# ATSAMC21N18A register map
Registers are 32-bit, access not given, no defined reset value unless marked. A register's access mark holds for its fields unless they carry their own. Addresses are absolute; registers are grouped by the start of their names; [hi:lo] are bit positions; {n}, {i} and the like mark numbered series.

## TSENS
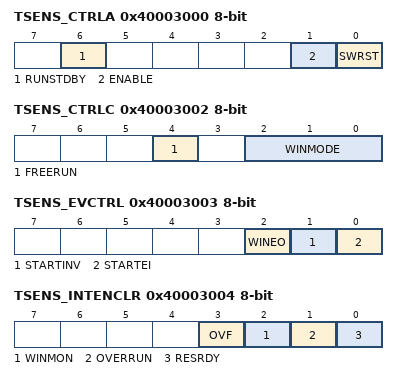
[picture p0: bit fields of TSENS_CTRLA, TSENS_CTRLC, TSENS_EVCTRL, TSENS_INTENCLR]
0x40003000 TSENS_CTRLA 8-bit — Control A Register
  [6] RUNSTDBY, [1] ENABLE, [0] SWRST
0x40003001 TSENS_CTRLB 8-bit — Control B Register
  [0] START
0x40003002 TSENS_CTRLC 8-bit — Control C Register
  [4] FREERUN, [2:0] WINMODE
0x40003003 TSENS_EVCTRL 8-bit — Event Control Register
  [2] WINEO, [1] STARTINV, [0] STARTEI
0x40003004 TSENS_INTENCLR 8-bit — Interrupt Enable Clear Register
  [3] OVF, [2] WINMON, [1] OVERRUN, [0] RESRDY
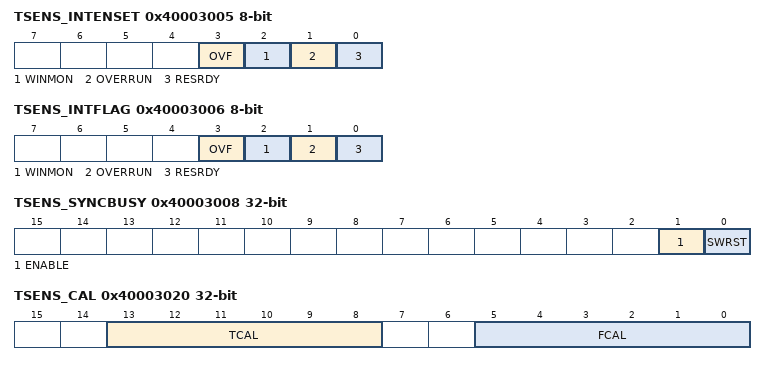
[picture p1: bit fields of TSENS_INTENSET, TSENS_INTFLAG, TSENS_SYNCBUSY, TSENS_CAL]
0x40003005 TSENS_INTENSET 8-bit — Interrupt Enable Set Register
  [3] OVF, [2] WINMON, [1] OVERRUN, [0] RESRDY
0x40003006 TSENS_INTFLAG 8-bit — Interrupt Flag Status and Clear Register
  [3] OVF, [2] WINMON, [1] OVERRUN, [0] RESRDY
0x40003007 TSENS_STATUS 8-bit — Status Register
  [0] OVF
0x40003008 TSENS_SYNCBUSY — Synchronization Busy Register
  [1] ENABLE, [0] SWRST
0x4000300C TSENS_VALUE — Value Register
  [23:0] VALUE
0x40003010 TSENS_WINLT — Window Monitor Lower Threshold Register
  [23:0] WINLT
0x40003014 TSENS_WINUT — Window Monitor Upper Threshold Register
  [23:0] WINUT
0x40003018 TSENS_GAIN — Gain Register
  [23:0] GAIN
0x4000301C TSENS_OFFSET — Offset Register
  [23:0] OFFSETC
0x40003020 TSENS_CAL — Calibration Register
  [13:8] TCAL, [5:0] FCAL
0x40003024 TSENS_DBGCTRL 8-bit — Debug Control Register
  [0] DBGRUN

## WDT
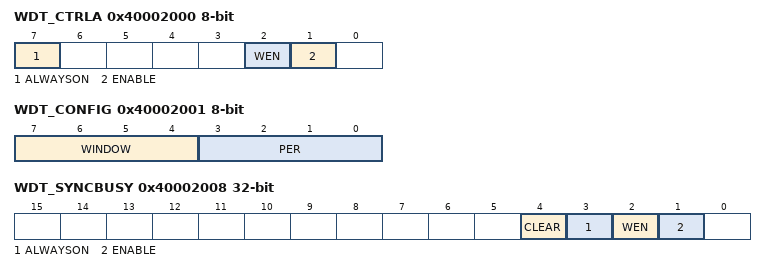
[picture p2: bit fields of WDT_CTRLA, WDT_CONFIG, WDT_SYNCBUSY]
0x40002000 WDT_CTRLA 8-bit — Control
  [7] ALWAYSON, [2] WEN, [1] ENABLE
0x40002001 WDT_CONFIG 8-bit — Configuration
  [7:4] WINDOW, [3:0] PER
0x40002002 WDT_EWCTRL 8-bit — Early Warning Interrupt Control
  [3:0] EWOFFSET
0x40002004 WDT_INTENCLR 8-bit — Interrupt Enable Clear
  [0] EW
0x40002005 WDT_INTENSET 8-bit — Interrupt Enable Set
  [0] EW
0x40002006 WDT_INTFLAG 8-bit — Interrupt Flag Status and Clear
  [0] EW
0x40002008 WDT_SYNCBUSY — Synchronization Busy
  [4] CLEAR, [3] ALWAYSON, [2] WEN, [1] ENABLE
0x4000200C WDT_CLEAR 8-bit — Clear

## MPU
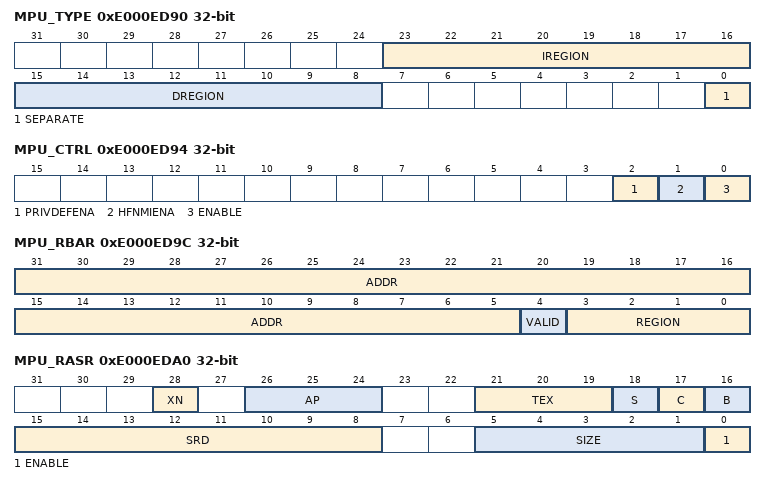
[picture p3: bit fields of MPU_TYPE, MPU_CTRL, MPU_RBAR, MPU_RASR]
0xE000ED90 MPU_TYPE
  [23:16] IREGION, [15:8] DREGION, [0] SEPARATE
0xE000ED94 MPU_CTRL — MPU Control Register
  [2] PRIVDEFENA, [1] HFNMIENA, [0] ENABLE
0xE000ED98 MPU_RNR — MPU Region Number Register
  [7:0] REGION
0xE000ED9C MPU_RBAR — MPU Region Base Address Register
  [31:5] ADDR, [4] VALID, [3:0] REGION
0xE000EDA0 MPU_RASR — MPU Region Attribute and Size Register
  [28] XN, [26:24] AP, [21:19] TEX, [18] S, [17] C, [16] B, [15:8] SRD, [5:1] SIZE, [0] ENABLE

## NVIC
0xE000E100 NVIC_ISER — Interrupt Set Enable Register
  [30:0] SETENA
0xE000E180 NVIC_ICER — Interrupt Clear Enable Register
  [30:0] CLRENA
0xE000E200 NVIC_ISPR — Interrupt Set Pending Register
  [30:0] SETPEND
0xE000E280 NVIC_ICPR — Interrupt Clear Pending Register
  [30:0] CLRPEND
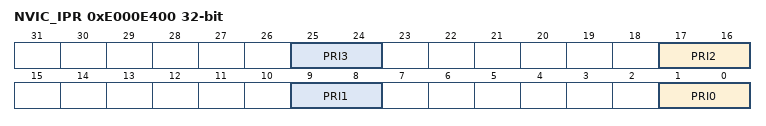
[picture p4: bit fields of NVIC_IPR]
0xE000E400 NVIC_IPR — Interrupt Priority Register n
  [8n+1:8n] PRI{n} (n=0..3)

## SysTick
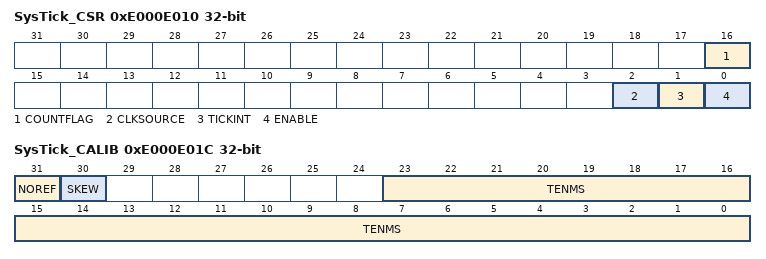
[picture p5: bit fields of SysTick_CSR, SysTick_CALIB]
0xE000E010 SysTick_CSR — SysTick Control and Status Register
  [16] COUNTFLAG, [2] CLKSOURCE, [1] TICKINT, [0] ENABLE
0xE000E014 SysTick_RVR — SysTick Reload Value Register
  [23:0] RELOAD
0xE000E018 SysTick_CVR — SysTick Current Value Register
  [23:0] CURRENT
0xE000E01C SysTick_CALIB — SysTick Calibration Value Register
  [31] NOREF, [30] SKEW, [23:0] TENMS

## SystemControl
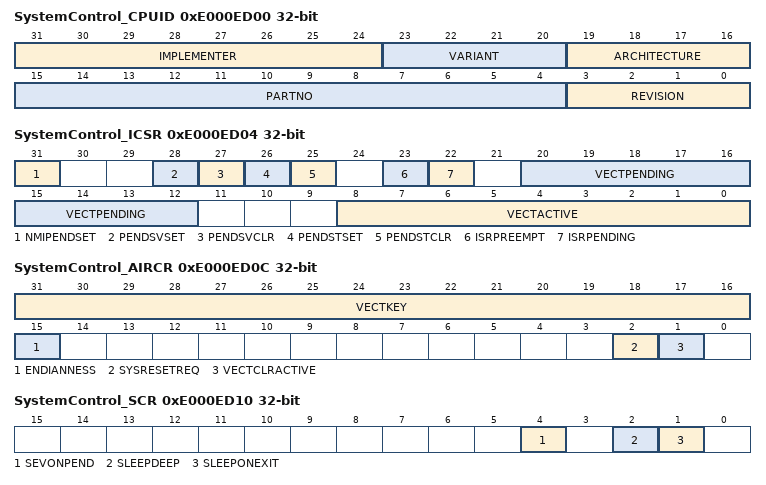
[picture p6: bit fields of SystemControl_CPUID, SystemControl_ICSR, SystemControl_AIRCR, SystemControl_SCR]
0xE000ED00 SystemControl_CPUID — CPUID Base Register
  [31:24] IMPLEMENTER, [23:20] VARIANT, [19:16] ARCHITECTURE, [15:4] PARTNO, [3:0] REVISION
0xE000ED04 SystemControl_ICSR — Interrupt Control and State Register
  [31] NMIPENDSET, [28] PENDSVSET, [27] PENDSVCLR, [26] PENDSTSET, [25] PENDSTCLR, [23] ISRPREEMPT, [22] ISRPENDING, [20:12] VECTPENDING, [8:0] VECTACTIVE
0xE000ED08 SystemControl_VTOR — Vector Table Offset Register
  [31:7] TBLOFF
0xE000ED0C SystemControl_AIRCR — Application Interrupt and Reset Control Register
  [31:16] VECTKEY, [15] ENDIANNESS, [2] SYSRESETREQ, [1] VECTCLRACTIVE
0xE000ED10 SystemControl_SCR — System Control Register
  [4] SEVONPEND, [2] SLEEPDEEP, [1] SLEEPONEXIT
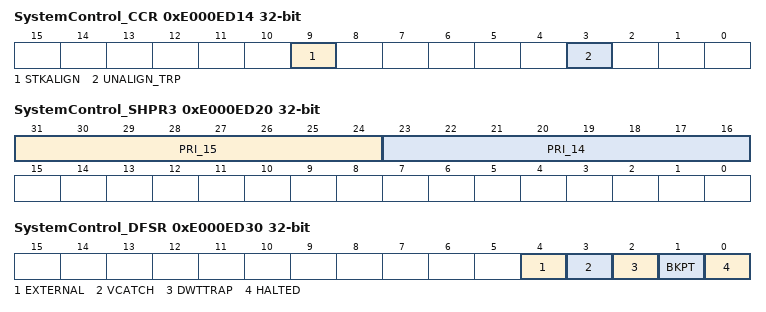
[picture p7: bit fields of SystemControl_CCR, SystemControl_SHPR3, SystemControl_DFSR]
0xE000ED14 SystemControl_CCR — Configuration and Control Register
  [9] STKALIGN, [3] UNALIGN_TRP
0xE000ED1C SystemControl_SHPR2 — System Handler Priority Register 2
  [31:24] PRI_11
0xE000ED20 SystemControl_SHPR3 — System Handler Priority Register 3
  [31:24] PRI_15, [23:16] PRI_14
0xE000ED24 SystemControl_SHCSR — System Handler Control and State Register
  [15] SVCALLPENDED
0xE000ED30 SystemControl_DFSR — Debug Fault Status Register
  [4] EXTERNAL, [3] VCATCH, [2] DWTTRAP, [1] BKPT, [0] HALTED

## SFR
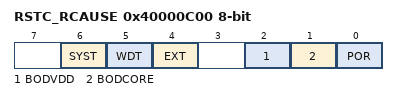
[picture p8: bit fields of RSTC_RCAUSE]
0x40000C00 RSTC_RCAUSE 8-bit — Reset Cause
  [6] SYST, [5] WDT, [4] EXT, [2] BODVDD, [1] BODCORE, [0] POR
